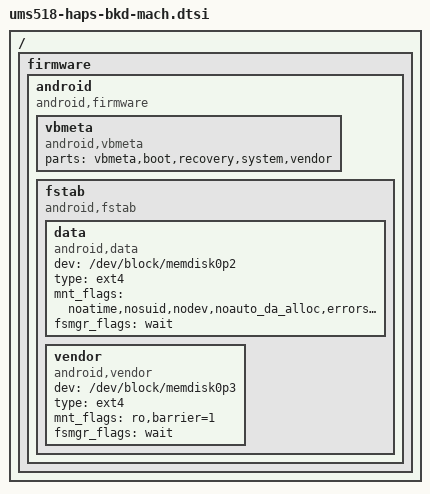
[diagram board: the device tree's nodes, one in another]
/*
 * Spreadtrum Sharkl5Pro board common DTS file
 *
 * Copyright (C) 2018, Spreadtrum Communications Inc.
 *
 * This file is licensed under a dual GPLv2 or X11 license.
 */

/ {
	firmware {
		android {
			compatible = "android,firmware";

			vbmeta {
				compatible = "android,vbmeta";
				parts = "vbmeta,boot,recovery,system,vendor";
			};

			fstab {
				compatible = "android,fstab";

				data {
					compatible = "android,data";
					dev = "/dev/block/memdisk0p2";
					type = "ext4";
					mnt_flags = "noatime,nosuid,nodev,noauto_da_alloc,errors=panic";
					fsmgr_flags = "wait";
				};

				vendor {
					compatible = "android,vendor";
					dev = "/dev/block/memdisk0p3";
					type = "ext4";
					mnt_flags = "ro,barrier=1";
					fsmgr_flags = "wait";
				};
			};
		};
	};
};
